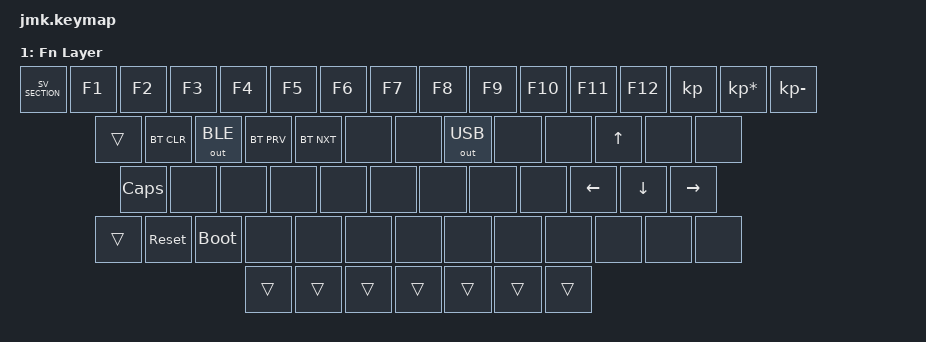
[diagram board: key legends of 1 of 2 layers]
/*
 * Copyright (c) 2020 The ZMK Contributors
 *
 * SPDX-License-Identifier: MIT
 */
#include "keys_sv.h"
//#include <behaviors.dtsi>
#include <dt-bindings/zmk/keys.h>
#include <dt-bindings/zmk/bt.h>
#include <dt-bindings/zmk/outputs.h>

/ {
    keymap {
        compatible = "zmk,keymap";

            default_layer {
                    display-name = "Default Layer";
            // ------------------------------------------------------------------------------------------
            // | ESC |  1  |  2  |  3  |  4  |  5  |  6  |  7  |  8  |  9  |  0  |  +  |  ´  | ' | BSPC |
            // | TAB  |  Q  |  W  |  E  |  R  |  T  |  Y  |  U  |  I  |  O  |  P  |  Å  |  ^  |         |
            // | CAPS  |  A  |  S  |  D  |  F  |  G  |  H  |  J  |  K  |  L  |  Ö  |  Ä  |     ENTER    |
            // |SHIFT| < |  Z  |  X  |  C  |  V  |  B  |  N  |  M  |  ,  |  .  |  -  |      SHIFT       |
            // |  CTL  |  SUPER  |  ALT  |                SPACE                 |  ALT  |  FN   |  CTL  |
            // ------------------------------------------------------------------------------------------
                        bindings = <
                &KP ESC  &kp SV_N1 &kp SV_N2 &kp SV_N3 &kp SV_N4 &kp SV_N5 &kp SV_N6 &kp SV_N7 &kp SV_N8 &kp SV_N9 &kp SV_N0 &kp SV_PLUS &kp SV_ACUTE  &kp SV_SINGLE_QUOTE  &kp BSPC
                &kp TAB  &kp Q  &kp W  &kp E  &kp R  &kp T  &kp Y  &kp U  &kp I  &kp O  &kp P  &kp SV_A_RING  &kp SV_CARET
                &kp INSERT  &kp A  &kp S  &kp D  &kp F  &kp G  &kp H  &kp J  &kp K  &kp L  &kp SV_O_UMLAUT  &kp SV_A_UMLAUT
                &kp LSHFT &kp SV_LESS_THAN  &kp Z  &kp X  &kp C  &kp V  &kp B  &kp N  &kp M  &kp SV_COMMA  &kp SV_PERIOD  &kp SV_MINUS  &kp RSHFT
                &kp LCTRL &kp LGUI &kp LALT             &kp SPACE                     &kp RALT   &mo LOWER   &kp RCTRL
            >;
        };

        lower {
            display-name = "Fn Layer";
            // ------------------------------------------------------------------------------------------
            // | ESC |  1  |  2  |  3  |  4  |  5  |  6  |  7  |  8  |  9  |  0  |  +  |  ´  | ' | BSPC |
            // | TAB  |  Q  |  W  |  E  |  R  |  T  |  Y  |  U  |  I  |  O  |  P  |  Å  |  ^  |         |
            // | CAPS  |  A  |  S  |  D  |  F  |  G  |  H  |  J  |  K  |  L  |  Ö  |  Ä  |     ENTER    |
            // |SHIFT| < |  Z  |  X  |  C  |  V  |  B  |  N  |  M  |  ,  |  .  |  -  |      SHIFT       |
            // |  CTL  |  SUPER  |  ALT  |                SPACE                 |  ALT  |  FN   |  CTL  |
            // ------------------------------------------------------------------------------------------
            bindings = <
                &kp SV_SECTION  &kp F1 &kp F2 &kp F3 &kp F4 &kp F5 &kp F6 &kp F7 &kp F8 &kp F9 &kp F10 &kp F11 &kp F12  &kp  &kp KP_MULTIPLY  &kp KP_MINUS
                &trans  &bt BT_CLR  &out OUT_BLE  &bt BT_PRV  &bt BT_NXT  &none  &none  &out OUT_USB  &none  &none  &kp UP  &none  &none
                &kp CAPS  &none  &none  &none  &none  &none  &none  &none  &none  &kp LEFT  &kp DOWN  &kp RIGHT
                &trans &sys_reset  &bootloader  &none  &none  &none  &none  &none &none  &none  &none  &none  &none
                &trans &trans &trans             &trans                     &trans   &trans   &trans
            >;
        };
	    >;
	};
};

